# KM1M7CF13 register map
Vendor: Nuvoton Technology Corporation Japan; Series: KM1M7CF; File version: 1.0.3
CPU: CM7 r1p2, little endian, MPU, FPU, double-precision FPU, I-cache, D-cache, ITCM, DTCM, 4 interrupt priority bits
Registers are 32-bit, read-write, no defined reset value unless marked. A register's access mark holds for its fields unless they carry their own. Offsets are from the block's base; [hi:lo] are bit positions; {n}, {i} and the like mark numbered series; 'fields as' and 'values as' point back to an identical list.

## ADC — A/D Converter
Base 0x40023000
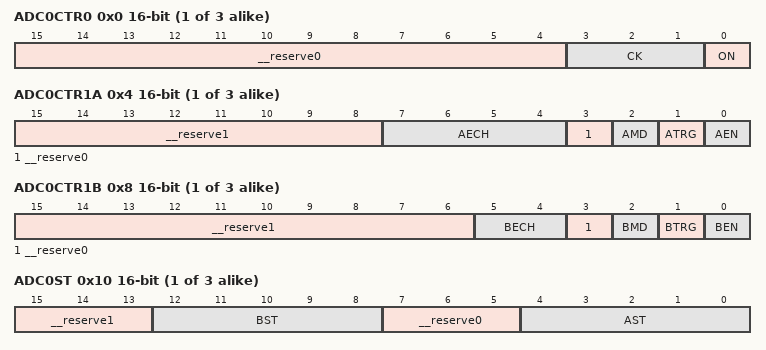
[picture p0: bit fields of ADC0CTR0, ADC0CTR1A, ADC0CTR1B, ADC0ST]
{0x0+0x100*i} ADC{i}CTR0 16-bit access per field (i=0..2) — A/D{i} Conversion Control Register 0
  [15:4] __reserve0 ro — "0" is always read out.
  [3:1] CK rw — ADCK selection
  [0] ON rw — A/Dn operation mode
{0x4+0x100*i} ADC{i}CTR1A 16-bit access per field (i=0..2) — A/D{i} Conversion Control Register 1A
  [15:8] __reserve1 ro — "0" is always read out.
  [7:4] AECH rw — Conversion end channel setting
  [3] __reserve0 ro — "0" is always read out.
  [2] AMD rw — Select A/D conversion mode
  [1] ATRG rw — A/D conversion start by using trigger A
  [0] AEN rw — A/D conversion start
{0x8+0x100*i} ADC{i}CTR1B 16-bit access per field (i=0..2) — A/D{i} Conversion Control Register 1B
  [15:6] __reserve1 ro — "0" is always read out.
  [5:4] BECH rw — Conversion end channel setting
  [3] __reserve0 ro — "0" is always read out.
  [2] BMD rw — A/D conversion mode select
  [1] BTRG rw — A/D conversion start by using trigger B
  [0] BEN rw — A/D conversion start
{0x10+0x100*i} ADC{i}ST 16-bit access per field (i=0..2) — A/D{i} Conversion Start Trigger Selection Register
  [15:13] __reserve1 ro — "0" is always read out.
  [12:8] BST rw — Start trigger B for A/Dn conversion
  [7:5] __reserve0 ro — "0" is always read out.
  [4:0] AST rw — Start trigger A for A/Dn conversion
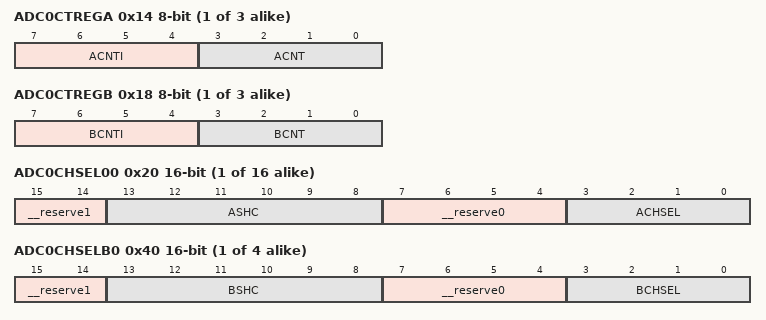
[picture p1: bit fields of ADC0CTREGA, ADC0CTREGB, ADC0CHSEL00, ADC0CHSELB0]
{0x14+0x100*i} ADC{i}CTREGA 8-bit (i=0..2) — A/D{i} Conversion Start Trigger A Count Register
  [7:4] ACNTI — The number of times trigger A is reduced (at the first A/D conversion)
  [3:0] ACNT — The number of times trigger A is reduced (at the second or later A/D conversion)
{0x18+0x100*i} ADC{i}CTREGB 8-bit (i=0..2) — A/D{i} Conversion Start Trigger B Count Register
  [7:4] BCNTI — The number of times trigger B is reduced (at the first A/D conversion)
  [3:0] BCNT — The number of times trigger B is reduced (at the second or later A/D conversion)
{0x20+2i} ADC0CHSEL{i:02} 16-bit access per field (i=0..15) — A/D0 Conversion Channel {i:02} Selection Register
  [15:14] __reserve1 ro — "0" is always read out.
  [13:8] ASHC rw — Sampling/Hold cycles
  [7:4] __reserve0 ro — "0" is always read out.
  [3:0] ACHSEL rw — Conversion channel selection
{0x40+2i} ADC0CHSELB{i} 16-bit access per field (i=0..3) — A/D0 Conversion Channel B{i} Selection Register
  [15:14] __reserve1 ro — "0" is always read out.
  [13:8] BSHC rw — Sampling/Hold cycles
  [7:4] __reserve0 ro — "0" is always read out.
  [3:0] BCHSEL rw — Conversion channel selection
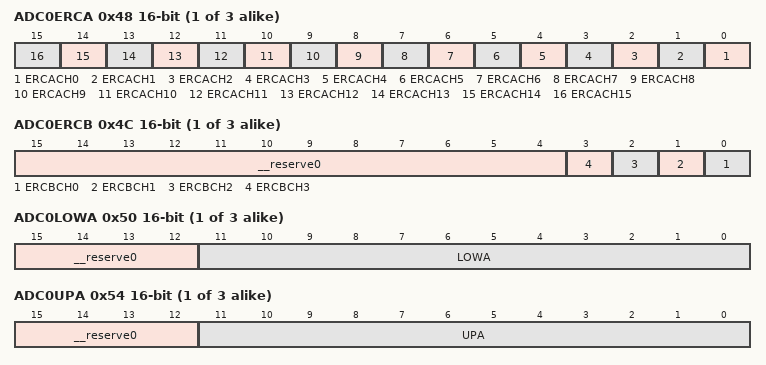
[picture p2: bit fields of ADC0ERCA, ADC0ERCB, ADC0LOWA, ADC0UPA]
{0x48+0x100*i} ADC{i}ERCA 16-bit (i=0..2) — A/D{i} Conversion Error Detection Channel Setting Register A
  [n] ERCACH{n} (n=0..15) — Error detection setting (the channel selected by setting ANnCHSEL{n:02}).
{0x4C+0x100*i} ADC{i}ERCB 16-bit access per field (i=0..2) — A/D{i} Conversion Error Detection Channel Setting Register B
  [15:4] __reserve0 ro — "0" is always read out.
  [n] ERCBCH{n} rw (n=0..3) — Error detection setting (the channel selected by setting ANnCHSELB{n}).
{0x50+0x100*i} ADC{i}LOWA 16-bit access per field (i=0..2) — A/D{i} Conversion Error Detection Lower Limit Setting Register A
  [15:12] __reserve0 ro — "0" is always read out.
  [11:0] LOWA rw — Set the lower limit of A/Dn conversion result (trigger A)
{0x54+0x100*i} ADC{i}UPA 16-bit access per field (i=0..2) — A/D{i} Conversion Error Detection Upper Limit Setting Register A
  [15:12] __reserve0 ro — "0" is always read out.
  [11:0] UPA rw — Set the upper limit of A/Dn conversion result (trigger A)
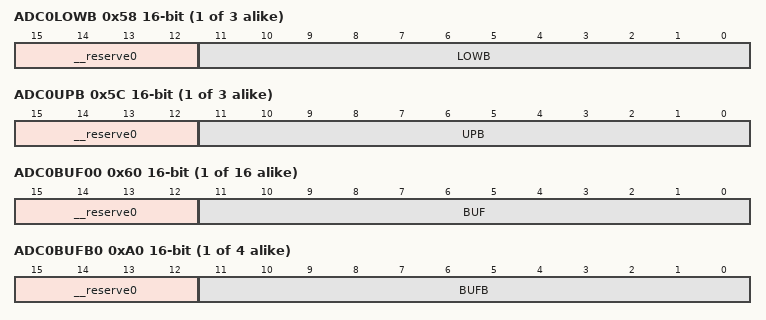
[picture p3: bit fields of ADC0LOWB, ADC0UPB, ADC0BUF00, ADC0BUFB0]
{0x58+0x100*i} ADC{i}LOWB 16-bit access per field (i=0..2) — A/D{i} Conversion Error Detection Lower Limit Setting Register B
  [15:12] __reserve0 ro — "0" is always read out.
  [11:0] LOWB rw — Set the lower limit of A/Dn conversion result (trigger B)
{0x5C+0x100*i} ADC{i}UPB 16-bit access per field (i=0..2) — A/D{i} Conversion Error Detection Upper Limit Setting Register B
  [15:12] __reserve0 ro — "0" is always read out.
  [11:0] UPB rw — Set the upper limit of A/Dn conversion result (trigger B)
{0x60+4i} ADC0BUF{i:02} 16-bit ro (i=0..15) — A/D0 Conversion Data Buffer {i:02} Register
  [15:12] __reserve0 — "0" is always read out.
  [11:0] BUF — A/D conversion results of the channel selected by ADC0CHSELm are stored.
{0xA0+4i} ADC0BUFB{i} 16-bit ro (i=0..3) — A/D0 Conversion Data Buffer B{i} Register
  [15:12] __reserve0 — "0" is always read out.
  [11:0] BUFB — A/D conversion results of the channel selected by ADC0CHSELBm are stored.
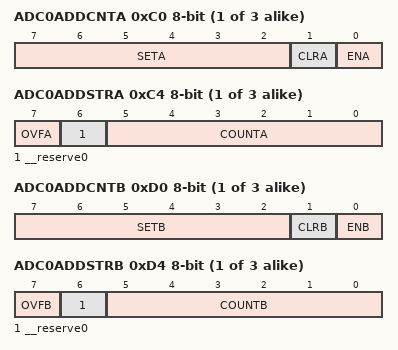
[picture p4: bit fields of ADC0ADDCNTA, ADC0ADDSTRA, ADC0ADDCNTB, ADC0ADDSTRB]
{0xC0+0x100*i} ADC{i}ADDCNTA 8-bit (i=0..2) — A/D{i} Conversion Result Addition Control Register A
  [7:2] SETA — Setting the number of times to add the conversion result for trigger A
  [1] CLRA — Clearing the addition result of the conversion result for trigger A
  [0] ENA — Adding the A/D conversion result for trigger A
{0xC4+0x100*i} ADC{i}ADDSTRA 8-bit ro (i=0..2) — A/D{i} Conversion Result Addition Status Register A
  [7] OVFA — Addition result overflow of conversion result for trigger A
  [6] __reserve0 — "0" is always read out.
  [5:0] COUNTA — Current count of conversion result addition for trigger A
{0xC8+0x100*i} ADC{i}ADDBUFA ro (i=0..2) — A/D{i} Addition Result Register A
  [31:0] BUFA — A/D conversion addition result for trigger A
{0xD0+0x100*i} ADC{i}ADDCNTB 8-bit (i=0..2) — A/D{i} Conversion Result Addition Control Register B
  [7:2] SETB — Setting the number of times to add the conversion result for trigger B
  [1] CLRB — Clearing the addition result of the conversion result for trigger B
  [0] ENB — Adding the A/D conversion result for trigger B
{0xD4+0x100*i} ADC{i}ADDSTRB 8-bit ro (i=0..2) — A/D{i} Conversion Result Addition Status Register B
  [7] OVFB — Addition result overflow of conversion result for trigger B
  [6] __reserve0 — "0" is always read out.
  [5:0] COUNTB — Current count of conversion result addition for trigger B
{0xD8+0x100*i} ADC{i}ADDBUFB ro (i=0..2) — A/D{i} Addition Result Register B
  [31:0] BUFB — A/D conversion addition result for trigger B
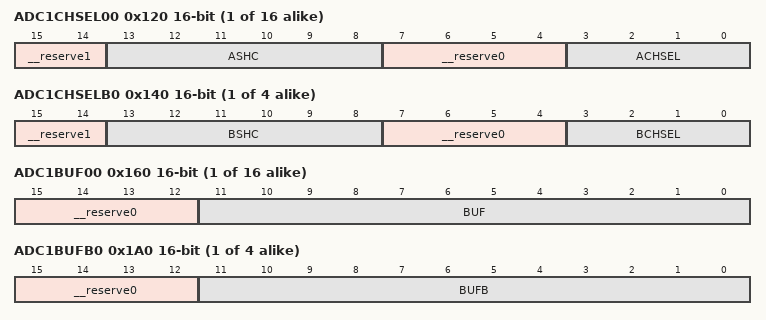
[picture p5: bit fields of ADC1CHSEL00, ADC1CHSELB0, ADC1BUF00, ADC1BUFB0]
{0x120+2i} ADC1CHSEL{i:02} 16-bit access per field (i=0..15) — A/D1 Conversion Channel {i:02} Selection Register
  fields as ADC0CHSEL00
{0x140+2i} ADC1CHSELB{i} 16-bit access per field (i=0..3) — A/D1 Conversion Channel B{i} Selection Register
  fields as ADC0CHSELB0
{0x160+4i} ADC1BUF{i:02} 16-bit ro (i=0..15) — A/D1 Conversion Data Buffer {i:02} Register
  [15:12] __reserve0 — "0" is always read out.
  [11:0] BUF — A/D conversion results of the channel selected by ADC1CHSELm are stored.
{0x1A0+4i} ADC1BUFB{i} 16-bit ro (i=0..3) — A/D1 Conversion Data Buffer B{i} Register
  [15:12] __reserve0 — "0" is always read out.
  [11:0] BUFB — A/D conversion results of the channel selected by ADC1CHSELBm are stored.
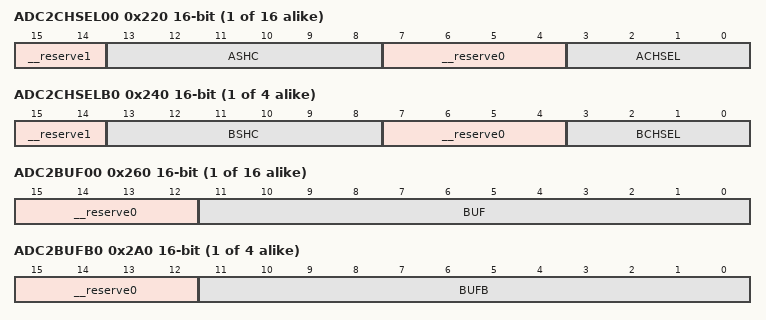
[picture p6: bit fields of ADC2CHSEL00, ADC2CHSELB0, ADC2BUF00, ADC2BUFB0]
{0x220+2i} ADC2CHSEL{i:02} 16-bit access per field (i=0..15) — A/D2 Conversion Channel {i:02} Selection Register
  fields as ADC0CHSEL00
{0x240+2i} ADC2CHSELB{i} 16-bit access per field (i=0..3) — A/D2 Conversion Channel B{i} Selection Register
  fields as ADC0CHSELB0
{0x260+4i} ADC2BUF{i:02} 16-bit ro (i=0..15) — A/D2 Conversion Data Buffer {i:02} Register
  [15:12] __reserve0 — "0" is always read out.
  [11:0] BUF — A/D conversion results of the channel selected by ADC2CHSELm are stored.
{0x2A0+4i} ADC2BUFB{i} 16-bit ro (i=0..3) — A/D2 Conversion Data Buffer B{i} Register
  [15:12] __reserve0 — "0" is always read out.
  [11:0] BUFB — A/D conversion results of the channel selected by ADC2CHSELBm are stored.
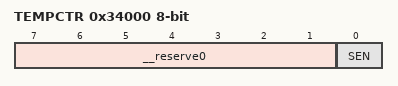
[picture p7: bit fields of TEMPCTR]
0x34000 TEMPCTR 8-bit access per field — Temperature Sensor Control Register
  [7:1] __reserve0 ro — "0" is always read out.
  [0] SEN rw — Temperature sensor enable
